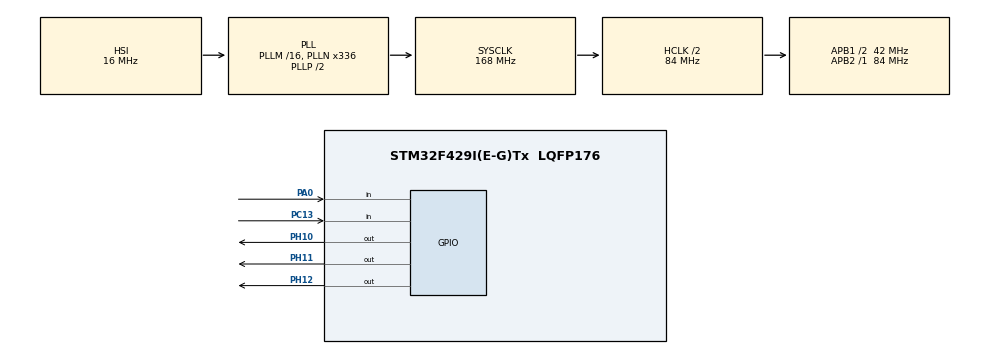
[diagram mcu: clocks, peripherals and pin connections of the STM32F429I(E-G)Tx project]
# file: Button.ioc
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Mcu.Family=STM32F4
Mcu.Name=STM32F429I(E-G)Tx
Mcu.Package=LQFP176
NVIC.PriorityGroup=NVIC_PRIORITYGROUP_4
NVIC.TIM5_IRQn=true\:0\:0\:false\:false\:true\:true\:true\:true
PA0/WKUP.Signal=GPIO_Input
PC13.Signal=GPIO_Input
PH10.Signal=GPIO_Output
PH11.Signal=GPIO_Output
PH12.Signal=GPIO_Output
ProjectManager.HeapSize=0x200
ProjectManager.StackSize=0x400
ProjectManager.TargetToolchain=STM32CubeIDE
RCC.48MHZClocksFreq_Value=84000000
RCC.AHBCLKDivider=RCC_SYSCLK_DIV2
RCC.AHBFreq_Value=84000000
RCC.APB1CLKDivider=RCC_HCLK_DIV2
RCC.APB1Freq_Value=42000000
RCC.APB1TimFreq_Value=84000000
RCC.APB2Freq_Value=84000000
RCC.APB2TimFreq_Value=84000000
RCC.CortexFreq_Value=84000000
RCC.HCLKFreq_Value=84000000
RCC.HSE_VALUE=25000000
RCC.HSI_VALUE=16000000
RCC.LSE_VALUE=32768
RCC.PLLN=336
RCC.SYSCLKFreq_VALUE=168000000
RCC.SYSCLKSource=RCC_SYSCLKSOURCE_PLLCLK
RCC.VCOOutputFreq_Value=336000000
TIM5.Period=999
TIM5.Prescaler=83
VP_TIM5_VS_ClockSourceINT.Mode=Internal
board=custom

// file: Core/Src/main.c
/* USER CODE BEGIN Header */
/**
  ******************************************************************************
  * @file           : main.c
  * @brief          : Main program body
  ******************************************************************************
  * @attention
  *
  * Copyright (c) 2025 STMicroelectronics.
  * All rights reserved.
  *
  * This software is licensed under terms that can be found in the LICENSE file
  * in the root directory of this software component.
  * If no LICENSE file comes with this software, it is provided AS-IS.
  *
  ******************************************************************************
  */
/* USER CODE END Header */
#include "main.h"
#include "tim.h"
#include "gpio.h"

void SystemClock_Config(void);

int main(void)
{

  /* MCU Configuration--------------------------------------------------------*/

  /* Reset of all peripherals, Initializes the Flash interface and the Systick. */
  HAL_Init();

  /* Configure the system clock */
  SystemClock_Config();

  /* Initialize all configured peripherals */
  MX_GPIO_Init();
  MX_TIM5_Init();
  /* USER CODE BEGIN 2 */
  // 啟動定時器中斷
  HAL_TIM_Base_Start_IT(&htim5);  // 啟動定時器 TIM5 並使能中斷
  /* USER CODE END 2 */

  /* Infinite loop */
  while (1)
  {

  }
}

void SystemClock_Config(void)
{
  RCC_OscInitTypeDef RCC_OscInitStruct = {0};
  RCC_ClkInitTypeDef RCC_ClkInitStruct = {0};

  /** Configure the main internal regulator output voltage
  */
  __HAL_RCC_PWR_CLK_ENABLE();
  __HAL_PWR_VOLTAGESCALING_CONFIG(PWR_REGULATOR_VOLTAGE_SCALE3);

  /** Initializes the RCC Oscillators according to the specified parameters
  * in the RCC_OscInitTypeDef structure.
  */
  RCC_OscInitStruct.OscillatorType = RCC_OSCILLATORTYPE_HSI;
  RCC_OscInitStruct.HSIState = RCC_HSI_ON;
  RCC_OscInitStruct.HSICalibrationValue = RCC_HSICALIBRATION_DEFAULT;
  RCC_OscInitStruct.PLL.PLLState = RCC_PLL_ON;
  RCC_OscInitStruct.PLL.PLLSource = RCC_PLLSOURCE_HSI;
  RCC_OscInitStruct.PLL.PLLM = 16;
  RCC_OscInitStruct.PLL.PLLN = 336;
  RCC_OscInitStruct.PLL.PLLP = RCC_PLLP_DIV2;
  RCC_OscInitStruct.PLL.PLLQ = 4;
  if (HAL_RCC_OscConfig(&RCC_OscInitStruct) != HAL_OK)
  {
    Error_Handler();
  }

  /** Initializes the CPU, AHB and APB buses clocks
  */
  RCC_ClkInitStruct.ClockType = RCC_CLOCKTYPE_HCLK|RCC_CLOCKTYPE_SYSCLK
                              |RCC_CLOCKTYPE_PCLK1|RCC_CLOCKTYPE_PCLK2;
  RCC_ClkInitStruct.SYSCLKSource = RCC_SYSCLKSOURCE_PLLCLK;
  RCC_ClkInitStruct.AHBCLKDivider = RCC_SYSCLK_DIV2;
  RCC_ClkInitStruct.APB1CLKDivider = RCC_HCLK_DIV2;
  RCC_ClkInitStruct.APB2CLKDivider = RCC_HCLK_DIV1;

  if (HAL_RCC_ClockConfig(&RCC_ClkInitStruct, FLASH_LATENCY_2) != HAL_OK)
  {
    Error_Handler();
  }
}

void Error_Handler(void)
{
  __disable_irq();
  while (1)
  {
  }
}
